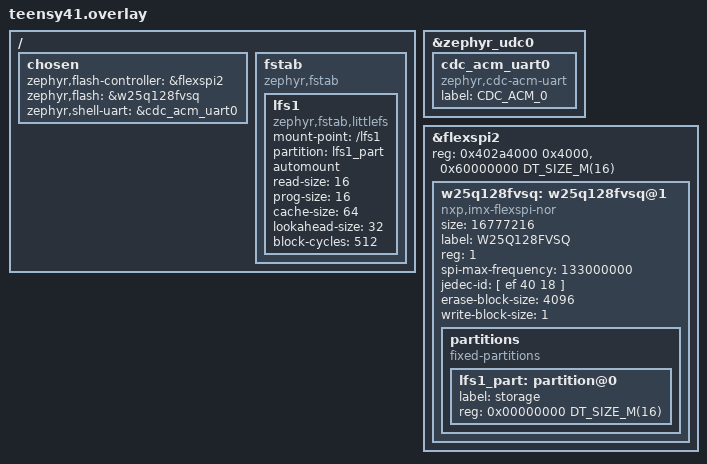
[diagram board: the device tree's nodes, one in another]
/ {
	chosen {
		zephyr,flash-controller = &flexspi2;
		zephyr,flash = &w25q128fvsq;
		zephyr,shell-uart = &cdc_acm_uart0;
	};
	fstab {
		compatible = "zephyr,fstab";
		lfs1: lfs1 {
			compatible = "zephyr,fstab,littlefs";
			mount-point = "/lfs1";
			partition = <&lfs1_part>;
			automount;
			read-size = <16>;
			prog-size = <16>;
			cache-size = <64>;
			lookahead-size = <32>;
			block-cycles = <512>;
		};
	};
};

&zephyr_udc0 {
	cdc_acm_uart0: cdc_acm_uart0 {
		compatible = "zephyr,cdc-acm-uart";
		label = "CDC_ACM_0";
	};
};

&flexspi2 {
	reg = <0x402a4000 0x4000>,<0x60000000 DT_SIZE_M(16)>; //probably wrong, check how a second flash chip needs its registers
	status = "okay";
	/* WINBOND flash memory*/
	w25q128fvsq: w25q128fvsq@1 {
		compatible = "nxp,imx-flexspi-nor";
		size = < 16777216 >;
		label = "W25Q128FVSQ";
		reg = < 1 >;
		spi-max-frequency = < 133000000 >;
		status = "okay";
		jedec-id = [ ef 40 18 ];
		erase-block-size = <4096>;
		write-block-size = <1>;

		partitions {
			compatible = "fixed-partitions";
			#address-cells = <1>;
			#size-cells = <1>;

			lfs1_part: partition@0 {
				label = "storage";
				reg = < 0x00000000 DT_SIZE_M(16) >;
			};
		};
	};
};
